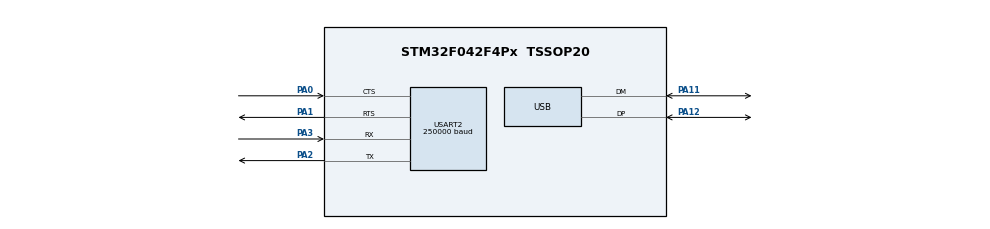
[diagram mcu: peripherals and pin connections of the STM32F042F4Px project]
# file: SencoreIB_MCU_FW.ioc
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Mcu.Family=STM32F0
Mcu.Name=STM32F042F4Px
Mcu.Package=TSSOP20
PA0.Mode=CTS_RTS
PA0.Signal=USART2_CTS
PA1.Mode=CTS_RTS
PA1.Signal=USART2_RTS
PA11.Mode=Device
PA11.Signal=USB_DM
PA12.Mode=Device
PA12.Signal=USB_DP
PA13.Mode=Serial_Wire
PA13.Signal=SYS_SWDIO
PA14.Mode=Serial_Wire
PA14.Signal=SYS_SWCLK
PA2.Mode=Asynchronous
PA2.Signal=USART2_TX
PA3.Mode=Asynchronous
PA3.Signal=USART2_RX
ProjectManager.HeapSize=0x200
ProjectManager.StackSize=0x800
ProjectManager.TargetToolchain=STM32CubeIDE
RCC.AHBFreq_Value=32000000
RCC.APB1Freq_Value=32000000
RCC.APB1TimFreq_Value=32000000
RCC.HCLKFreq_Value=32000000
RCC.PLLMUL=RCC_PLL_MUL4
RCC.SYSCLKFreq_VALUE=32000000
RCC.SYSCLKSource=RCC_SYSCLKSOURCE_PLLCLK
USART2.BaudRate=250000
USART2.VirtualMode-Asynchronous=VM_ASYNC
VP_SYS_VS_PINREMAP.Mode=PINREMAP
board=custom

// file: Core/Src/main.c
/* USER CODE BEGIN Header */
/**
  ******************************************************************************
  * @file           : main.c
  * @brief          : Main program body
  ******************************************************************************
  * @attention
  *
  * <h2><center>&copy; Copyright (c) 2019 STMicroelectronics.
  * All rights reserved.</center></h2>
  *
  * This software component is licensed by ST under BSD 3-Clause license,
  * the "License"; You may not use this file except in compliance with the
  * License. You may obtain a copy of the License at:
  *                        opensource.org/licenses/BSD-3-Clause
  *
  ******************************************************************************
  */
/* USER CODE END Header */

#include "main.h"
#include "usart.h"
#include "usb.h"
#include "gpio.h"

/* USER CODE BEGIN Includes */
#include "tusb.h"
#include "usbtmc_app.h"
/* USER CODE END Includes */

void SystemClock_Config(void);

/* USER CODE BEGIN 0 */
void TU_BREAKPOINT() {

}
/* USER CODE END 0 */

int main(void)
{

  /* MCU Configuration--------------------------------------------------------*/

  /* Reset of all peripherals, Initializes the Flash interface and the Systick. */
  HAL_Init();

  /* Configure the system clock */
  SystemClock_Config();

  /* Initialize all configured peripherals */
  MX_GPIO_Init();
  MX_USART2_UART_Init();
  /* USER CODE BEGIN 2 */
  __HAL_RCC_USB_CLK_ENABLE();
  //uart_tx_str_sync("Hello\r\n");
  tusb_init();
  /* USER CODE END 2 */

  /* Infinite loop */
  /* USER CODE BEGIN WHILE */
  while (1)
  {
	  tud_task();
	  usbtmc_app_task_iter();
    /* USER CODE END WHILE */

  }
}

void SystemClock_Config(void)
{
  LL_FLASH_SetLatency(LL_FLASH_LATENCY_1);

  if(LL_FLASH_GetLatency() != LL_FLASH_LATENCY_1)
  {
  Error_Handler();
  }
  LL_RCC_HSI_Enable();

   /* Wait till HSI is ready */
  while(LL_RCC_HSI_IsReady() != 1)
  {

  }
  LL_RCC_HSI_SetCalibTrimming(16);
  LL_RCC_HSI48_Enable();

   /* Wait till HSI48 is ready */
  while(LL_RCC_HSI48_IsReady() != 1)
  {

  }
  LL_RCC_PLL_ConfigDomain_SYS(LL_RCC_PLLSOURCE_HSI, LL_RCC_PLL_MUL_4, LL_RCC_PREDIV_DIV_1);
  LL_RCC_PLL_Enable();

   /* Wait till PLL is ready */
  while(LL_RCC_PLL_IsReady() != 1)
  {

  }
  LL_RCC_SetAHBPrescaler(LL_RCC_SYSCLK_DIV_1);
  LL_RCC_SetAPB1Prescaler(LL_RCC_APB1_DIV_1);
  LL_RCC_SetSysClkSource(LL_RCC_SYS_CLKSOURCE_PLL);

   /* Wait till System clock is ready */
  while(LL_RCC_GetSysClkSource() != LL_RCC_SYS_CLKSOURCE_STATUS_PLL)
  {

  }
  LL_SetSystemCoreClock(32000000);
  LL_RCC_SetUSBClockSource(LL_RCC_USB_CLKSOURCE_HSI48);
}

void Error_Handler(void)
{
}

/************************ (C) COPYRIGHT STMicroelectronics *****END OF FILE****/
